# Multiplier__32_Bit_Mode_1 register map
Vendor: Texas Instruments
Peripheral module from a debugger description file (folder msp430).
Registers are 16-bit, access not given, no defined reset value unless marked. A register's access mark holds for its fields unless they carry their own. Offsets are as the file gives them; lines under a group give offsets from that group; [hi:lo] are bit positions; {n}, {i} and the like mark numbered series; 'fields as' and 'values as' point back to an identical list; <NAME> marks a mode.

## Multiplier_32_Bit_Mode
0x140 MPY32L_B 8-bit — 32-bit operand 1 - multiply - low word (Byte Access)
0x140 MPY32L — 32-bit operand 1 - multiply - low word
0x142 MPY32H_B 8-bit — 32-bit operand 1 - multiply - high word (Byte Access)
0x142 MPY32H — 32-bit operand 1 - multiply - high word
0x144 MPYS32L_B 8-bit — 32-bit operand 1 - signed multiply - low word (Byte Access)
0x144 MPYS32L — 32-bit operand 1 - signed multiply - low word
0x146 MPYS32H_B 8-bit — 32-bit operand 1 - signed multiply - high word (Byte Access)
0x146 MPYS32H — 32-bit operand 1 - signed multiply - high word
0x148 MAC32L_B 8-bit — 32-bit operand 1 - multiply accumulate - low word (Byte Access)
0x148 MAC32L — 32-bit operand 1 - multiply accumulate - low word
0x14A MAC32H_B 8-bit — 32-bit operand 1 - multiply accumulate - high word (Byte Access)
0x14A MAC32H — 32-bit operand 1 - multiply accumulate - high word
0x14C MACS32L_B 8-bit — 32-bit operand 1 - signed multiply accumulate - low word (Byte Access)
0x14C MACS32L — 32-bit operand 1 - signed multiply accumulate - low word
0x14E MACS32H_B 8-bit — 32-bit operand 1 - signed multiply accumulate - high word (Byte Access)
0x14E MACS32H — 32-bit operand 1 - signed multiply accumulate - high word
0x150 OP2L_B 8-bit — 32-bit operand 2 - low word (Byte Access)
0x150 OP2L — 32-bit operand 2 - low word
0x152 OP2H_B 8-bit — 32-bit operand 2 - high word (Byte Access)
0x152 OP2H — 32-bit operand 2 - high word
0x154 RES0 — 32x32-bit result 0 - least significant word
0x156 RES1 — 32x32-bit result 1
0x158 RES2 — 32x32-bit result 2
0x15A RES3 — 32x32-bit result 3 - most significant word
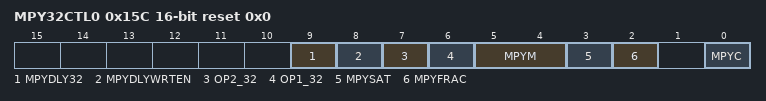
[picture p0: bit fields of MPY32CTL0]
0x15C MPY32CTL0 rw reset 0x0 — MPY32 Control Register 0
  [9] MPYDLY32 — Delayed write mode
  [8] MPYDLYWRTEN — Delayed write enable
  [7] OP2_32 — Bit-width of operand 2 0:16Bit / 1:32Bit
  [6] OP1_32 — Bit-width of operand 1 0:16Bit / 1:32Bit
  [5:4] MPYM — Multiplier mode Bit:0
    0=Multiplier mode: MPY; 1=Multiplier mode: MPYS; 2=Multiplier mode: MAC; 3=Multiplier mode: MACS
  [3] MPYSAT — Saturation mode
  [2] MPYFRAC — Fractional mode
  [0] MPYC — Carry of the multiplier
